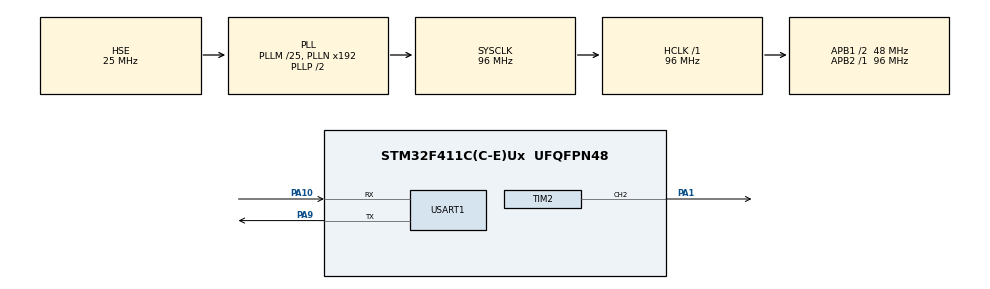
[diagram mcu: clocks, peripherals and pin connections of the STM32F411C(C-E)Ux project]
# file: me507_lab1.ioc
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Mcu.Family=STM32F4
Mcu.Name=STM32F411C(C-E)Ux
Mcu.Package=UFQFPN48
NVIC.PriorityGroup=NVIC_PRIORITYGROUP_4
NVIC.TIM2_IRQn=true\:0\:0\:false\:false\:true\:true\:true\:true
PA1.Signal=S_TIM2_CH2
PA10.Mode=Asynchronous
PA10.Signal=USART1_RX
PA13.Mode=Trace_Asynchronous_SW
PA13.Signal=SYS_JTMS-SWDIO
PA14.Mode=Trace_Asynchronous_SW
PA14.Signal=SYS_JTCK-SWCLK
PA9.Mode=Asynchronous
PA9.Signal=USART1_TX
PB3.Mode=Trace_Asynchronous_SW
PB3.Signal=SYS_JTDO-SWO
PH0\ -\ OSC_IN.Mode=HSE-External-Oscillator
PH0\ -\ OSC_IN.Signal=RCC_OSC_IN
PH1\ -\ OSC_OUT.Mode=HSE-External-Oscillator
PH1\ -\ OSC_OUT.Signal=RCC_OSC_OUT
ProjectManager.HeapSize=0x200
ProjectManager.StackSize=0x400
ProjectManager.TargetToolchain=STM32CubeIDE
RCC.48MHZClocksFreq_Value=48000000
RCC.AHBFreq_Value=96000000
RCC.APB1CLKDivider=RCC_HCLK_DIV2
RCC.APB1Freq_Value=48000000
RCC.APB1TimFreq_Value=96000000
RCC.APB2Freq_Value=96000000
RCC.APB2TimFreq_Value=96000000
RCC.CortexFreq_Value=96000000
RCC.HCLKFreq_Value=96000000
RCC.HSE_VALUE=25000000
RCC.HSI_VALUE=16000000
RCC.LSE_VALUE=32768
RCC.PLLM=25
RCC.PLLSourceVirtual=RCC_PLLSOURCE_HSE
RCC.SYSCLKFreq_VALUE=96000000
RCC.SYSCLKSource=RCC_SYSCLKSOURCE_PLLCLK
RCC.VCOOutputFreq_Value=192000000
SH.S_TIM2_CH2.0=TIM2_CH2,PWM Generation2 CH2
TIM2.AutoReloadPreload=TIM_AUTORELOAD_PRELOAD_ENABLE
TIM2.Channel-PWM\ Generation2\ CH2=TIM_CHANNEL_2
TIM2.Period=47999999
TIM2.Pulse-PWM\ Generation2\ CH2=19200000 
TIM2.TIM_MasterOutputTrigger=TIM_TRGO_OC1
USART1.VirtualMode=VM_ASYNC
VP_TIM2_VS_ClockSourceINT.Mode=Internal
VP_TIM9_VS_ClockSourceITR.Mode=TriggerSource_ITR0
VP_TIM9_VS_ControllerModeClock.Mode=Clock Mode
board=custom

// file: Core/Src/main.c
/* USER CODE BEGIN Header */
/**
  ******************************************************************************
  * @file           : main.c
  * @brief          : Main program body
  ******************************************************************************
  * @attention
  *
  * Copyright (c) 2025 STMicroelectronics.
  * All rights reserved.
  *
  * This software is licensed under terms that can be found in the LICENSE file
  * in the root directory of this software component.
  * If no LICENSE file comes with this software, it is provided AS-IS.
  *
  ******************************************************************************
  */
/* USER CODE END Header */
#include "main.h"

TIM_HandleTypeDef htim2;
TIM_HandleTypeDef htim9;

UART_HandleTypeDef huart1;

/* USER CODE BEGIN PV */
uint32_t PWM_duty_cycle = 4800;
uint32_t counterValue = 0;

/* USER CODE END PV */

void SystemClock_Config(void);
static void MX_GPIO_Init(void);
static void MX_TIM2_Init(void);
static void MX_TIM9_Init(void);
static void MX_USART1_UART_Init(void);

/* USER CODE BEGIN 0 */
char tx_buff[64];
/* USER CODE END 0 */

int main(void)
{

  /* MCU Configuration--------------------------------------------------------*/

  /* Reset of all peripherals, Initializes the Flash interface and the Systick. */
  HAL_Init();

  /* Configure the system clock */
  SystemClock_Config();

  /* Initialize all configured peripherals */
  MX_GPIO_Init();
  MX_TIM2_Init();
  MX_TIM9_Init();
  MX_USART1_UART_Init();
  /* USER CODE BEGIN 2 */
  HAL_TIM_PWM_Start_IT(&htim2, TIM_CHANNEL_2);
  HAL_TIM_Base_Start(&htim9);
  /* USER CODE END 2 */

  /* Infinite loop */
  /* USER CODE BEGIN WHILE */
  while (1)
  {
	  __HAL_TIM_SET_COMPARE(&htim2, TIM_CHANNEL_2, PWM_duty_cycle);
	  HAL_Delay(100);
    /* USER CODE END WHILE */

  }
}

void SystemClock_Config(void)
{
  RCC_OscInitTypeDef RCC_OscInitStruct = {0};
  RCC_ClkInitTypeDef RCC_ClkInitStruct = {0};

  /** Configure the main internal regulator output voltage
  */
  __HAL_RCC_PWR_CLK_ENABLE();
  __HAL_PWR_VOLTAGESCALING_CONFIG(PWR_REGULATOR_VOLTAGE_SCALE1);

  /** Initializes the RCC Oscillators according to the specified parameters
  * in the RCC_OscInitTypeDef structure.
  */
  RCC_OscInitStruct.OscillatorType = RCC_OSCILLATORTYPE_HSE;
  RCC_OscInitStruct.HSEState = RCC_HSE_ON;
  RCC_OscInitStruct.PLL.PLLState = RCC_PLL_ON;
  RCC_OscInitStruct.PLL.PLLSource = RCC_PLLSOURCE_HSE;
  RCC_OscInitStruct.PLL.PLLM = 25;
  RCC_OscInitStruct.PLL.PLLN = 192;
  RCC_OscInitStruct.PLL.PLLP = RCC_PLLP_DIV2;
  RCC_OscInitStruct.PLL.PLLQ = 4;
  if (HAL_RCC_OscConfig(&RCC_OscInitStruct) != HAL_OK)
  {
    Error_Handler();
  }

  /** Initializes the CPU, AHB and APB buses clocks
  */
  RCC_ClkInitStruct.ClockType = RCC_CLOCKTYPE_HCLK|RCC_CLOCKTYPE_SYSCLK
                              |RCC_CLOCKTYPE_PCLK1|RCC_CLOCKTYPE_PCLK2;
  RCC_ClkInitStruct.SYSCLKSource = RCC_SYSCLKSOURCE_PLLCLK;
  RCC_ClkInitStruct.AHBCLKDivider = RCC_SYSCLK_DIV1;
  RCC_ClkInitStruct.APB1CLKDivider = RCC_HCLK_DIV2;
  RCC_ClkInitStruct.APB2CLKDivider = RCC_HCLK_DIV1;

  if (HAL_RCC_ClockConfig(&RCC_ClkInitStruct, FLASH_LATENCY_3) != HAL_OK)
  {
    Error_Handler();
  }
}

static void MX_TIM2_Init(void)
{

  TIM_ClockConfigTypeDef sClockSourceConfig = {0};
  TIM_MasterConfigTypeDef sMasterConfig = {0};
  TIM_OC_InitTypeDef sConfigOC = {0};

  htim2.Instance = TIM2;
  htim2.Init.Prescaler = 0;
  htim2.Init.CounterMode = TIM_COUNTERMODE_UP;
  htim2.Init.Period = 47999999;
  htim2.Init.ClockDivision = TIM_CLOCKDIVISION_DIV1;
  htim2.Init.AutoReloadPreload = TIM_AUTORELOAD_PRELOAD_ENABLE;
  if (HAL_TIM_Base_Init(&htim2) != HAL_OK)
  {
    Error_Handler();
  }
  sClockSourceConfig.ClockSource = TIM_CLOCKSOURCE_INTERNAL;
  if (HAL_TIM_ConfigClockSource(&htim2, &sClockSourceConfig) != HAL_OK)
  {
    Error_Handler();
  }
  if (HAL_TIM_PWM_Init(&htim2) != HAL_OK)
  {
    Error_Handler();
  }
  sMasterConfig.MasterOutputTrigger = TIM_TRGO_OC1;
  sMasterConfig.MasterSlaveMode = TIM_MASTERSLAVEMODE_DISABLE;
  if (HAL_TIMEx_MasterConfigSynchronization(&htim2, &sMasterConfig) != HAL_OK)
  {
    Error_Handler();
  }
  sConfigOC.OCMode = TIM_OCMODE_PWM1;
  sConfigOC.Pulse = 19200000 ;
  sConfigOC.OCPolarity = TIM_OCPOLARITY_HIGH;
  sConfigOC.OCFastMode = TIM_OCFAST_DISABLE;
  if (HAL_TIM_PWM_ConfigChannel(&htim2, &sConfigOC, TIM_CHANNEL_2) != HAL_OK)
  {
    Error_Handler();
  }
  HAL_TIM_MspPostInit(&htim2);

}

static void MX_TIM9_Init(void)
{

  TIM_SlaveConfigTypeDef sSlaveConfig = {0};

  htim9.Instance = TIM9;
  htim9.Init.Prescaler = 0;
  htim9.Init.CounterMode = TIM_COUNTERMODE_UP;
  htim9.Init.Period = 65535;
  htim9.Init.ClockDivision = TIM_CLOCKDIVISION_DIV1;
  htim9.Init.AutoReloadPreload = TIM_AUTORELOAD_PRELOAD_DISABLE;
  if (HAL_TIM_Base_Init(&htim9) != HAL_OK)
  {
    Error_Handler();
  }
  sSlaveConfig.SlaveMode = TIM_SLAVEMODE_EXTERNAL1;
  sSlaveConfig.InputTrigger = TIM_TS_ITR0;
  if (HAL_TIM_SlaveConfigSynchro(&htim9, &sSlaveConfig) != HAL_OK)
  {
    Error_Handler();
  }

}

static void MX_USART1_UART_Init(void)
{

  huart1.Instance = USART1;
  huart1.Init.BaudRate = 115200;
  huart1.Init.WordLength = UART_WORDLENGTH_8B;
  huart1.Init.StopBits = UART_STOPBITS_1;
  huart1.Init.Parity = UART_PARITY_NONE;
  huart1.Init.Mode = UART_MODE_TX_RX;
  huart1.Init.HwFlowCtl = UART_HWCONTROL_NONE;
  huart1.Init.OverSampling = UART_OVERSAMPLING_16;
  if (HAL_UART_Init(&huart1) != HAL_OK)
  {
    Error_Handler();
  }

}

static void MX_GPIO_Init(void)
{

  /* GPIO Ports Clock Enable */
  __HAL_RCC_GPIOH_CLK_ENABLE();
  __HAL_RCC_GPIOA_CLK_ENABLE();
  __HAL_RCC_GPIOB_CLK_ENABLE();

}

/* USER CODE BEGIN 4 */
void HAL_TIM_PWM_PulseFinishedCallback(TIM_HandleTypeDef *htim)
{
	counterValue = __HAL_TIM_GET_COUNTER(&htim9);
	sprintf(tx_buff, "LED HAS BLINKED %lu TIMES\r\n", counterValue);  // Format string with variable
	HAL_UART_Transmit(&huart1, (uint8_t*)tx_buff, strlen(tx_buff), 1000);

}
/* USER CODE END 4 */

void Error_Handler(void)
{
  __disable_irq();
  while (1)
  {
  }
}
